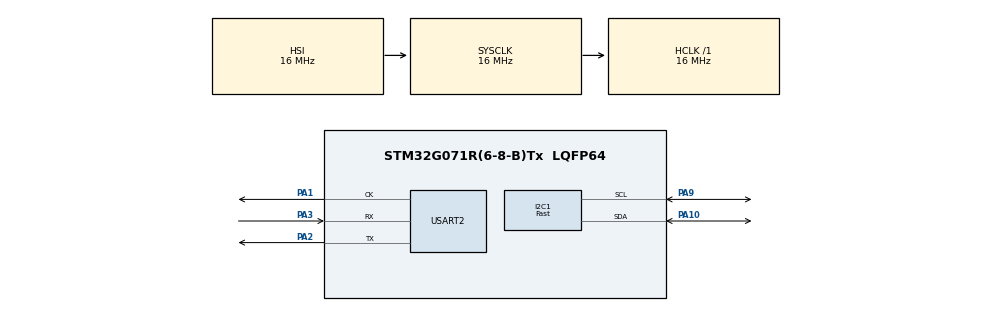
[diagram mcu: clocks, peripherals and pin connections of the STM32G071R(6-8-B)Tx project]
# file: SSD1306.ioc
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Dma.I2C1_TX.0.Direction=DMA_MEMORY_TO_PERIPH
Dma.I2C1_TX.0.EventEnable=DISABLE
Dma.I2C1_TX.0.Instance=DMA1_Channel6
Dma.I2C1_TX.0.MemDataAlignment=DMA_MDATAALIGN_BYTE
Dma.I2C1_TX.0.MemInc=DMA_MINC_ENABLE
Dma.I2C1_TX.0.Mode=DMA_NORMAL
Dma.I2C1_TX.0.PeriphDataAlignment=DMA_PDATAALIGN_BYTE
Dma.I2C1_TX.0.PeriphInc=DMA_PINC_DISABLE
Dma.I2C1_TX.0.Polarity=HAL_DMAMUX_REQ_GEN_RISING
Dma.I2C1_TX.0.Priority=DMA_PRIORITY_MEDIUM
Dma.I2C1_TX.0.RequestNumber=1
Dma.I2C1_TX.0.SignalID=NONE
Dma.I2C1_TX.0.SyncEnable=DISABLE
Dma.I2C1_TX.0.SyncPolarity=HAL_DMAMUX_SYNC_NO_EVENT
Dma.I2C1_TX.0.SyncRequestNumber=1
Dma.I2C1_TX.0.SyncSignalID=NONE
Dma.Request0=I2C1_TX
I2C1.I2C_Speed_Mode=I2C_Fast
I2C1.Timing=0x0010061A
Mcu.Family=STM32G0
Mcu.Name=STM32G071R(6-8-B)Tx
Mcu.Package=LQFP64
NVIC.DMA1_Ch4_7_DMAMUX1_OVR_IRQn=true\:0\:0\:false\:false\:true\:false\:true\:true
NVIC.I2C1_IRQn=true\:0\:0\:false\:false\:true\:true\:true\:true
PA1.Mode=Synchronous
PA1.Signal=USART2_CK
PA10.GPIO_Pu=GPIO_NOPULL
PA10.GPIO_Speed=GPIO_SPEED_FREQ_HIGH
PA10.Mode=I2C
PA10.Signal=I2C1_SDA
PA2.Mode=Synchronous
PA2.Signal=USART2_TX
PA3.Mode=Synchronous
PA3.Signal=USART2_RX
PA9.GPIO_Pu=GPIO_NOPULL
PA9.GPIO_Speed=GPIO_SPEED_FREQ_HIGH
PA9.Mode=I2C
PA9.Signal=I2C1_SCL
ProjectManager.HeapSize=0x200
ProjectManager.StackSize=0x400
ProjectManager.TargetToolchain=STM32CubeIDE
RCC.AHBFreq_Value=16000000
RCC.CortexFreq_Value=16000000
RCC.EXTERNAL_CLOCK_VALUE=48000
RCC.HCLKFreq_Value=16000000
RCC.HSE_VALUE=8000000
RCC.HSI_VALUE=16000000
RCC.LSE_VALUE=32768
RCC.SYSCLKFreq_VALUE=16000000
RCC.VCOOutputFreq_Value=128000000
USART2.VirtualMode-Synchronous=VM_SYNC
board=custom

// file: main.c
/* USER CODE BEGIN Header */
/**
  ******************************************************************************
  * @file           : main.c
  * @brief          : Main program body
  ******************************************************************************
  * @attention
  *
  * Copyright (c) 2023 STMicroelectronics.
  * All rights reserved.
  *
  * This software is licensed under terms that can be found in the LICENSE file
  * in the root directory of this software component.
  * If no LICENSE file comes with this software, it is provided AS-IS.
  *
  ******************************************************************************
  */
/* USER CODE END Header */
#include "main.h"
#include "dma.h"
#include "i2c.h"
#include "usart.h"
#include "gpio.h"

/* USER CODE BEGIN Includes */
#include "GFX.h"
/* USER CODE END Includes */

void SystemClock_Config(void);

int main(void)
{

  /* MCU Configuration--------------------------------------------------------*/

  /* Reset of all peripherals, Initializes the Flash interface and the Systick. */
  HAL_Init();

  /* Configure the system clock */
  SystemClock_Config();

  /* Initialize all configured peripherals */
  MX_GPIO_Init();
  MX_DMA_Init();
  MX_I2C1_Init();
  MX_USART2_Init();
  /* USER CODE BEGIN 2 */
  SSD1306_init();
  //GFX_draw_fill_rect(0, 0, 64, 32, WHITE);
  //GFX_draw_fill_rect(64, 32, 64, 32, WHITE);
  GFX_draw_string(1, 50, (unsigned char *)"* Hello :) *", WHITE, BLACK, 1, 1);
  GFX_draw_string(1, 40, (unsigned char *)"__________________", WHITE, BLACK, 1, 1);
  GFX_draw_string(2, 30, (unsigned char *)"> a:Bruma Mihai  <", WHITE, BLACK, 1, 1);
  GFX_draw_string(3, 20, (unsigned char *)"> Embedded C <", WHITE, BLACK, 1, 1);
  GFX_draw_string(1, 10, (unsigned char *)"__________________", WHITE, BLACK, 1, 1);
  GFX_draw_string(5, 0, (unsigned char *)"  ->->->->->  ", WHITE, BLACK, 1, 1);
  SSD1306_display_repaint();
  /* USER CODE END 2 */

  /* Infinite loop */
  while (1)
  {

  }
}

void SystemClock_Config(void)
{
  RCC_OscInitTypeDef RCC_OscInitStruct = {0};
  RCC_ClkInitTypeDef RCC_ClkInitStruct = {0};

  /** Configure the main internal regulator output voltage
  */
  HAL_PWREx_ControlVoltageScaling(PWR_REGULATOR_VOLTAGE_SCALE1);

  /** Initializes the RCC Oscillators according to the specified parameters
  * in the RCC_OscInitTypeDef structure.
  */
  RCC_OscInitStruct.OscillatorType = RCC_OSCILLATORTYPE_HSI;
  RCC_OscInitStruct.HSIState = RCC_HSI_ON;
  RCC_OscInitStruct.HSIDiv = RCC_HSI_DIV1;
  RCC_OscInitStruct.HSICalibrationValue = RCC_HSICALIBRATION_DEFAULT;
  RCC_OscInitStruct.PLL.PLLState = RCC_PLL_NONE;
  if (HAL_RCC_OscConfig(&RCC_OscInitStruct) != HAL_OK)
  {
    Error_Handler();
  }

  /** Initializes the CPU, AHB and APB buses clocks
  */
  RCC_ClkInitStruct.ClockType = RCC_CLOCKTYPE_HCLK|RCC_CLOCKTYPE_SYSCLK
                              |RCC_CLOCKTYPE_PCLK1;
  RCC_ClkInitStruct.SYSCLKSource = RCC_SYSCLKSOURCE_HSI;
  RCC_ClkInitStruct.AHBCLKDivider = RCC_SYSCLK_DIV1;
  RCC_ClkInitStruct.APB1CLKDivider = RCC_HCLK_DIV1;

  if (HAL_RCC_ClockConfig(&RCC_ClkInitStruct, FLASH_LATENCY_0) != HAL_OK)
  {
    Error_Handler();
  }
}

void Error_Handler(void)
{
  __disable_irq();
  while (1)
  {
  }
}
